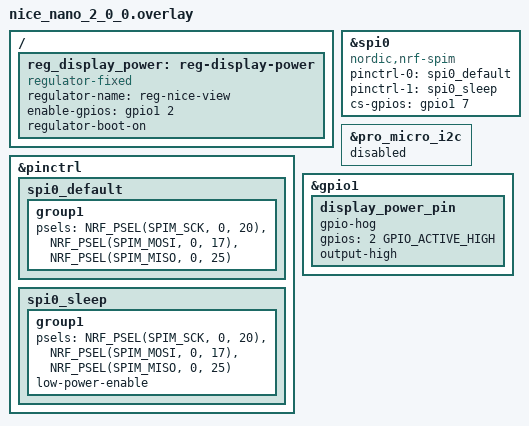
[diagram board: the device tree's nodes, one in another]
/*
 * Copyright (c) 2022 The ZMK Contributors
 *
 * SPDX-License-Identifier: MIT
 */

&pinctrl {
    spi0_default: spi0_default {
        group1 {
            psels = <NRF_PSEL(SPIM_SCK, 0, 20)>,
                <NRF_PSEL(SPIM_MOSI, 0, 17)>,
                <NRF_PSEL(SPIM_MISO, 0, 25)>;
        };
    };
    spi0_sleep: spi0_sleep {
        group1 {
            psels = <NRF_PSEL(SPIM_SCK, 0, 20)>,
                <NRF_PSEL(SPIM_MOSI, 0, 17)>,
                <NRF_PSEL(SPIM_MISO, 0, 25)>;
            low-power-enable;
        };
    };
};

nice_view_spi: &spi0 {
    compatible = "nordic,nrf-spim";
    pinctrl-0 = <&spi0_default>;
    pinctrl-1 = <&spi0_sleep>;
    pinctrl-names = "default", "sleep";
    cs-gpios = <&gpio1 7 GPIO_ACTIVE_HIGH>;
};

&pro_micro_i2c {
    status = "disabled";
};

&gpio1 {
     display_power_pin: display_power_pin {
         gpio-hog;
         gpios = <2 GPIO_ACTIVE_HIGH>;
         output-high;
     };
};

/ {
    reg_display_power: reg-display-power {
        compatible = "regulator-fixed";
        regulator-name = "reg-nice-view";
        enable-gpios = <&gpio1 2 GPIO_ACTIVE_HIGH>;
        regulator-boot-on;
    };
};
